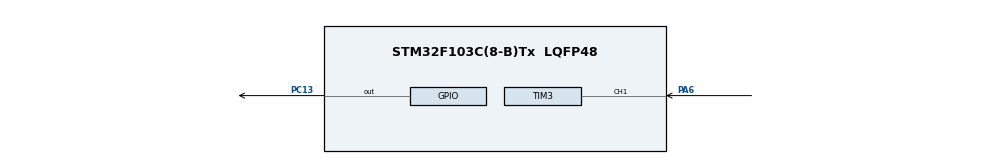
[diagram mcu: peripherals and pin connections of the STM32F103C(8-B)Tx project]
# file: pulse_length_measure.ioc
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Mcu.Family=STM32F1
NVIC.TIM3_IRQn=true\:0\:0\:false\:false\:true\:true\:true
RCC.APB2Freq_Value=8000000
PA14.Mode=Serial_Wire
TIM3.Prescaler=7
SH.S_TIM3_CH1.0=TIM3_CH1,Input_Capture1_from_TI1
PC13-TAMPER-RTC.Signal=GPIO_Output
PA13.Mode=Serial_Wire
Mcu.Name=STM32F103C(8-B)Tx
Mcu.Package=LQFP48
PA6.Signal=S_TIM3_CH1
ProjectManager.StackSize=0x400
PA13.Signal=SYS_JTMS-SWDIO
PA14.Signal=SYS_JTCK-SWCLK
ProjectManager.HeapSize=0x200
ProjectManager.TargetToolchain=STM32CubeIDE
NVIC.PriorityGroup=NVIC_PRIORITYGROUP_4
RCC.APB1Freq_Value=8000000
VP_TIM3_VS_ClockSourceINT.Mode=Internal
TIM3.Channel-Input_Capture1_from_TI1=TIM_CHANNEL_1
board=custom

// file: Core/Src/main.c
/* USER CODE BEGIN Header */
/**
  ******************************************************************************
  * @file           : main.c
  * @brief          : Main program body
  ******************************************************************************
  * @attention
  *
  * <h2><center>&copy; Copyright (c) 2021 STMicroelectronics.
  * All rights reserved.</center></h2>
  *
  * This software component is licensed by ST under BSD 3-Clause license,
  * the "License"; You may not use this file except in compliance with the
  * License. You may obtain a copy of the License at:
  *                        opensource.org/licenses/BSD-3-Clause
  *
  ******************************************************************************
  */
/* USER CODE END Header */
#include "main.h"

/* USER CODE BEGIN Includes */
#include <stdint.h>
/* USER CODE END Includes */

TIM_HandleTypeDef htim3;

/* USER CODE BEGIN PV */
uint32_t diff;
uint32_t captures[2];
volatile uint8_t first_capture = 0;
volatile float pulse_length;
/* USER CODE END PV */

void SystemClock_Config(void);
static void MX_GPIO_Init(void);
static void MX_TIM3_Init(void);

int main(void)
{

  /* MCU Configuration--------------------------------------------------------*/

  /* Reset of all peripherals, Initializes the Flash interface and the Systick. */
  HAL_Init();

  /* Configure the system clock */
  SystemClock_Config();

  /* Initialize all configured peripherals */
  MX_GPIO_Init();
  MX_TIM3_Init();
  /* USER CODE BEGIN 2 */
  HAL_TIM_IC_Start_IT(&htim3, TIM_CHANNEL_1);

  /* USER CODE END 2 */

  /* Infinite loop */
  while (1)
  {

    /* USER CODE BEGIN 3 */
	  HAL_GPIO_TogglePin(GPIOC, GPIO_PIN_13);
	  HAL_Delay(10);
  }
  /* USER CODE END 3 */
}

void SystemClock_Config(void)
{
  RCC_OscInitTypeDef RCC_OscInitStruct = {0};
  RCC_ClkInitTypeDef RCC_ClkInitStruct = {0};

  /** Initializes the RCC Oscillators according to the specified parameters
  * in the RCC_OscInitTypeDef structure.
  */
  RCC_OscInitStruct.OscillatorType = RCC_OSCILLATORTYPE_HSI;
  RCC_OscInitStruct.HSIState = RCC_HSI_ON;
  RCC_OscInitStruct.HSICalibrationValue = RCC_HSICALIBRATION_DEFAULT;
  RCC_OscInitStruct.PLL.PLLState = RCC_PLL_NONE;
  if (HAL_RCC_OscConfig(&RCC_OscInitStruct) != HAL_OK)
  {
    Error_Handler();
  }
  /** Initializes the CPU, AHB and APB buses clocks
  */
  RCC_ClkInitStruct.ClockType = RCC_CLOCKTYPE_HCLK|RCC_CLOCKTYPE_SYSCLK
                              |RCC_CLOCKTYPE_PCLK1|RCC_CLOCKTYPE_PCLK2;
  RCC_ClkInitStruct.SYSCLKSource = RCC_SYSCLKSOURCE_HSI;
  RCC_ClkInitStruct.AHBCLKDivider = RCC_SYSCLK_DIV1;
  RCC_ClkInitStruct.APB1CLKDivider = RCC_HCLK_DIV1;
  RCC_ClkInitStruct.APB2CLKDivider = RCC_HCLK_DIV1;

  if (HAL_RCC_ClockConfig(&RCC_ClkInitStruct, FLASH_LATENCY_0) != HAL_OK)
  {
    Error_Handler();
  }
}

static void MX_TIM3_Init(void)
{

  TIM_ClockConfigTypeDef sClockSourceConfig = {0};
  TIM_MasterConfigTypeDef sMasterConfig = {0};
  TIM_IC_InitTypeDef sConfigIC = {0};

  htim3.Instance = TIM3;
  htim3.Init.Prescaler = 7;
  htim3.Init.CounterMode = TIM_COUNTERMODE_UP;
  htim3.Init.Period = 65535;
  htim3.Init.ClockDivision = TIM_CLOCKDIVISION_DIV1;
  htim3.Init.AutoReloadPreload = TIM_AUTORELOAD_PRELOAD_DISABLE;
  if (HAL_TIM_Base_Init(&htim3) != HAL_OK)
  {
    Error_Handler();
  }
  sClockSourceConfig.ClockSource = TIM_CLOCKSOURCE_INTERNAL;
  if (HAL_TIM_ConfigClockSource(&htim3, &sClockSourceConfig) != HAL_OK)
  {
    Error_Handler();
  }
  if (HAL_TIM_IC_Init(&htim3) != HAL_OK)
  {
    Error_Handler();
  }
  sMasterConfig.MasterOutputTrigger = TIM_TRGO_RESET;
  sMasterConfig.MasterSlaveMode = TIM_MASTERSLAVEMODE_DISABLE;
  if (HAL_TIMEx_MasterConfigSynchronization(&htim3, &sMasterConfig) != HAL_OK)
  {
    Error_Handler();
  }
  sConfigIC.ICPolarity = TIM_INPUTCHANNELPOLARITY_RISING;
  sConfigIC.ICSelection = TIM_ICSELECTION_DIRECTTI;
  sConfigIC.ICPrescaler = TIM_ICPSC_DIV1;
  sConfigIC.ICFilter = 0;
  if (HAL_TIM_IC_ConfigChannel(&htim3, &sConfigIC, TIM_CHANNEL_1) != HAL_OK)
  {
    Error_Handler();
  }

}

static void MX_GPIO_Init(void)
{
  GPIO_InitTypeDef GPIO_InitStruct = {0};

  /* GPIO Ports Clock Enable */
  __HAL_RCC_GPIOC_CLK_ENABLE();
  __HAL_RCC_GPIOA_CLK_ENABLE();

  /*Configure GPIO pin Output Level */
  HAL_GPIO_WritePin(GPIOC, GPIO_PIN_13, GPIO_PIN_RESET);

  /*Configure GPIO pin : PC13 */
  GPIO_InitStruct.Pin = GPIO_PIN_13;
  GPIO_InitStruct.Mode = GPIO_MODE_OUTPUT_PP;
  GPIO_InitStruct.Pull = GPIO_NOPULL;
  GPIO_InitStruct.Speed = GPIO_SPEED_FREQ_LOW;
  HAL_GPIO_Init(GPIOC, &GPIO_InitStruct);

}

/* USER CODE BEGIN 4 */
void HAL_TIM_IC_CaptureCallback(TIM_HandleTypeDef *htim)
{
	if(htim->Channel == HAL_TIM_ACTIVE_CHANNEL_1)
	{
		if(!first_capture)
		{
			captures[0] = HAL_TIM_ReadCapturedValue(htim, TIM_CHANNEL_1);

			first_capture = 1;

			// Now change the polarity to falling edge
			__HAL_TIM_SET_CAPTUREPOLARITY(htim, TIM_CHANNEL_1, TIM_INPUTCHANNELPOLARITY_FALLING);
		}
		else
		{
			captures[1] = HAL_TIM_ReadCapturedValue(htim, TIM_CHANNEL_1);

			diff = (captures[0] < captures[1]) ?
					captures[1] - captures[0] :
					(htim->Instance->ARR - captures[0]) + captures[1];
			pulse_length = (float)diff * 1000 / (HAL_RCC_GetPCLK1Freq() / (htim->Instance->PSC + 1));;

			first_capture = 0;

			// Set polarity to rising edge
			__HAL_TIM_SET_CAPTUREPOLARITY(htim, TIM_CHANNEL_1, TIM_INPUTCHANNELPOLARITY_RISING);
		}
	}
}
/* USER CODE END 4 */

void Error_Handler(void)
{
  __disable_irq();
  while (1)
  {
  }
}

/************************ (C) COPYRIGHT STMicroelectronics *****END OF FILE****/
